# D1H.pdf register map
Vendor: Allwinner; Series: D1H.pdf; File version: 0.1
CPU: XuanTie C906 RISC-V CPU 0, little endian, MPU, FPU, double-precision FPU, 0 interrupt priority bits
Registers are 32-bit, read-write, reset 0x0 unless marked. A register's access mark holds for its fields unless they carry their own. Offsets are from the block's base; [hi:lo] are bit positions; lines under a group give offsets from that group; {n}, {i} and the like mark numbered series; 'fields as' and 'values as' point back to an identical list.

## LRADC
Base 0x02009800
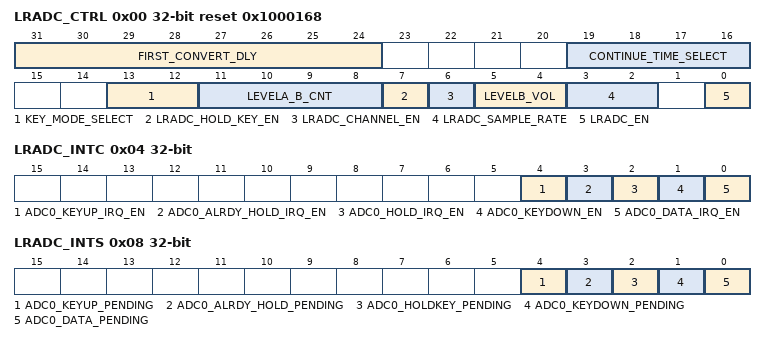
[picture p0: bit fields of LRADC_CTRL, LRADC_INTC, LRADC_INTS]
0x00 LRADC_CTRL reset 0x1000168 — LRADC Control Register
  [31:24] FIRST_CONVERT_DLY — ADC First Convert Delay Setting ADC conversion is delayed by n samples.
  [19:16] CONTINUE_TIME_SELECT — Continuous Mode Time Select One of 8*(N+1) sample as a valuable sample data.
  [13:12] KEY_MODE_SELECT — Key Mode Select 00: Normal Mode 01: Single Mode 10: Continuous Mode
    0=Normal Mode; 1=Single Mode; 2=Continuous Mode
  [11:8] LEVELA_B_CNT — Level A to Level B time threshold select Judge the ADC convert value from level A to level B in n+1 samples.
  [7] LRADC_HOLD_KEY_EN — LRADC Hold KEY Enable 0: Disable 1: Enable
    0=Disable; 1=Enable
  [6] LRADC_CHANNEL_EN — LRADC Channel Enable 0: Disable 1: Enable
    0=Disable; 1=Enable
  [5:4] LEVELB_VOL — Level B Corresponding Data Value Setting (the real voltage value) 00: Reserved 01: 0x39 (1.221 V) 10: 0x36 (1.157 V) 11: 0x33 (1.093 V)
    1=0x39 (1.221 V); 2=0x36 (1.157 V); 3=0x33 (1.093 V)
  [3:2] LRADC_SAMPLE_RATE — LRADC Sample Rate 00: 2 kHz 01: 1 kHz 10: 500 Hz 11: 250 Hz
    0=_2_kHz; 1=_1_kHz; 2=500 Hz; 3=250 Hz
  [0] LRADC_EN — LRADC Enable 0: Disable 1: Enable
    0=Disable; 1=Enable
0x04 LRADC_INTC — LRADC Interrupt Control Register
  [all] fields
    0=Disable; 1=Enable
  [4] ADC0_KEYUP_IRQ_EN — ADC0 Key Up IRQ Enable 0: Disable 1: Enable
  [3] ADC0_ALRDY_HOLD_IRQ_EN — ADC0 Already Hold Key IRQ Enable 0: Disable 1: Enable
  [2] ADC0_HOLD_IRQ_EN — ADC0 Hold Key IRQ Enable 0: Disable 1: Enable
  [1] ADC0_KEYDOWN_EN — ADC0 Key Down Enable 0: Disable 1: Enable
  [0] ADC0_DATA_IRQ_EN — ADC0 Data IRQ Enable 0: Disable 1: Enable
0x08 LRADC_INTS — LRADC Interrupt Status Register
  [4] ADC0_KEYUP_PENDING write-1-clears — ADC0 Key up Pending Bit When the general key is pulled up, and the corresponding interrupt is enabled, the status bit is set. 0: No IRQ 1: IRQ Pending Writing 1 to the bit will clear it and its corresponding interrupt if the interrupt is enabled.
    0=No_IRQ; 1=IRQ (IRQ Pending Writing 1 to the bit will clear it and its corresponding interrupt if the interrupt is enabled.)
  [3] ADC0_ALRDY_HOLD_PENDING write-1-clears — ADC0 Already Hold Pending Bit When the hold key is pulled down and the general key is pulled down, and the corresponding interrupt is enabled. 0: No IRQ 1: IRQ Pending Writing 1 to the bit will clear it and its corresponding interrupt if the interrupt is enabled.
    values as ADC0_KEYUP_PENDING
  [2] ADC0_HOLDKEY_PENDING write-1-clears — ADC0 Hold Key Pending Bit When the hold key is pulled down, and the corresponding interrupt is enabled, the status bit is set and the interrupt line is set. 0: NO IRQ 1: IRQ Pending Writing 1 to the bit will clear it and its corresponding interrupt if the interrupt is enabled.
    0=NO_IRQ; 1=IRQ (IRQ Pending Writing 1 to the bit will clear it and its corresponding interrupt if the interrupt is enabled.)
  [1] ADC0_KEYDOWN_PENDING write-1-clears — ADC0 Key Down IRQ Pending Bit When the general key is pulled down, and the corresponding interrupt is enabled, the status bit is set and the interrupt line is set. 0: No IRQ 1: IRQ Pending Writing 1 to the bit will clear it and its corresponding interrupt if the interrupt is enabled.
    values as ADC0_KEYUP_PENDING
  [0] ADC0_DATA_PENDING write-1-clears — ADC0 Data IRQ Pending Bit 0: No IRQ 1: IRQ Pending Writing 1 to the bit will clear it and its corresponding interrupt if the interrupt is enabled.
    values as ADC0_KEYUP_PENDING
0x0C LRADC_DATA reset 0x3F
  [5:0] LRADC_DATA ro

## RISCV_PLIC
Base 0x10000000
{0x0+4i} PLIC_PRIO_REGn_{i} (i=1..255) — PLIC_PRIO_REGn_{i}
  [0] PLIC_PRIO — PLIC Priority Support for 32 different levels of priority. Where, a priority sets to 0 indicates that the interrupt is invalid. Machine mode interrupts have unconditionally higher priority than super-user mode interrupts. When the interrupt target mode is the same, priority 1 is the lowest priority, priority 31 is the highest priority. When multiple interrupts of the same priority are waiting arbitration, the interrupt source ID is compared. The smaller ID has the higher priority.
{0x1000+4i} _n[{i}] (i=0..8) group
  0x00 PLIC_IP_REGn
    [31:0] PLIC_IP — PLIC Interrupt Pending.
  0x1000 PLIC_MIE_REGn
    [31:0] PLIC_MIE — PLIC Machine Mode Interrupt Enable.
  0x1080 PLIC_SIE_REGn
    [31:0] PLIC_SIE — PLIC Superuser Mode Interrupt Enable.
0x1FFFFC PLIC_CTRL_REG — PLIC Control Register
  [0] PLIC_CTRL — PLIC Control 0: Only the machine mode can access to all registers in PLIC. The super-user mode can not access PLIC_CTRL, PLIC_PRIO, PLIC_IP, and PLIC_IE registers, only access the interrupt threshold register and the interrupt response/completion register. The normal-user mode can not access any registers in PLIC. 1: The machine mode can access to all registers in PLIC. The super- user mode can access all registers except PLL_CTRL in PLIC. The normal-user mode can not access any registers in PLIC.
    0=Only the machine mode can access to all registers in PLIC. The super-user mode can not access PLIC_CTRL, PLIC_PRIO, PLIC_IP, and PLIC_IE registers, only access the interrupt threshold register and the interrupt response/completion register. The normal-user mode can not access any registers in PLIC.; 1=machine_mode (The machine mode can access to all registers in PLIC. The super- user mode can access all registers except PLL_CTRL in PLIC. The normal-user mode can not access any registers in PLIC.)
0x200000 PLIC_MTH_REG — PLIC Machine Threshold Register
  [4:0] PLIC_MTH — PLIC Machine Threshold Indicate the interrupt threshold of the current interrupt mode. If the threshold is configured to 0, it indicates that all interrupts are permitted.
0x200004 PLIC_MCLAIM_REG — PLIC Machine Claim Register
  [9:0] PLIC_MCLAIM — PLIC Machine Claim Read register: Return the current stored ID value of the register. The read operation indicates that the interrupt of the corresponding ID starts to perform. The PLIC starts to process the interrupt response. Write register: Indicate that the interrupt of the corresponding ID is complete. The writing operation can not update the response/completion register. The PLIC starts to process the interrupt completion.
0x201000 PLIC_STH_REG — PLIC Superuser Threshold Register
  [4:0] PLIC_STH — PLIC Superuser Threshold. Indicate the interrupt threshold of the current interrupt mode. If the threshold is configured to 0, it indicates that all interrupts are permitted.
0x201004 PLIC_SCLAIM_REG — PLIC Superuser Claim Register
  [9:0] PLIC_SCLAIM — PLIC Superuser Claim. Read register: Return the current stored ID value of the register. The read operation indicates that the interrupt of the corresponding ID starts to perform. The PLIC starts to process the interrupt response. Write register: Indicate that the interrupt of the corresponding ID is complete. The writing operation can not update the response/completion register. The PLIC starts to process the interrupt completion.
